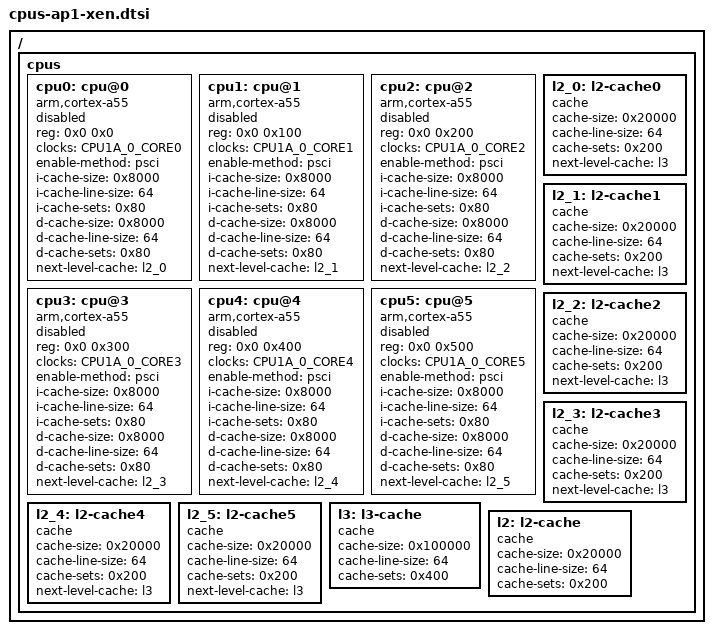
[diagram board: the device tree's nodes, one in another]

/ {
        cpus {
		#address-cells = <2>;
		#size-cells = <0>;

		cpu0: cpu@0 {
			device_type = "cpu";
			compatible = "arm,cortex-a55", "arm,armv8";
			reg = <0x0 0x0>;
			clocks = <&CPU1A_0_CORE0>;
			clock-names = "cpu0";
			enable-method = "psci";
			i-cache-size = <0x8000>;
			i-cache-line-size = <64>;
			i-cache-sets = <0x80>;
			d-cache-size = <0x8000>;
			d-cache-line-size = <64>;
			d-cache-sets = <0x80>;
			next-level-cache = <&l2_0>;
			status = "disabled";
		};

		cpu1: cpu@1 {
			device_type = "cpu";
			compatible = "arm,cortex-a55", "arm,armv8";
			reg = <0x0 0x100>;
			clocks = <&CPU1A_0_CORE1>;
			clock-names = "cpu1";
			enable-method = "psci";
			i-cache-size = <0x8000>;
			i-cache-line-size = <64>;
			i-cache-sets = <0x80>;
			d-cache-size = <0x8000>;
			d-cache-line-size = <64>;
			d-cache-sets = <0x80>;
			next-level-cache = <&l2_1>;
			status = "disabled";
		};

		cpu2: cpu@2 {
			device_type = "cpu";
			compatible = "arm,cortex-a55", "arm,armv8";
			reg = <0x0 0x200>;
			clocks = <&CPU1A_0_CORE2>;
			clock-names = "cpu2";
			enable-method = "psci";
			i-cache-size = <0x8000>;
			i-cache-line-size = <64>;
			i-cache-sets = <0x80>;
			d-cache-size = <0x8000>;
			d-cache-line-size = <64>;
			d-cache-sets = <0x80>;
			next-level-cache = <&l2_2>;
			status = "disabled";
		};

		cpu3: cpu@3 {
			device_type = "cpu";
			compatible = "arm,cortex-a55", "arm,armv8";
			reg = <0x0 0x300>;
			clocks = <&CPU1A_0_CORE3>;
			clock-names = "cpu3";
			enable-method = "psci";
			i-cache-size = <0x8000>;
			i-cache-line-size = <64>;
			i-cache-sets = <0x80>;
			d-cache-size = <0x8000>;
			d-cache-line-size = <64>;
			d-cache-sets = <0x80>;
			next-level-cache = <&l2_3>;
			status = "disabled";
		};

		cpu4: cpu@4 {
			device_type = "cpu";
			compatible = "arm,cortex-a55", "arm,armv8";
			reg = <0x0 0x400>;
			clocks = <&CPU1A_0_CORE4>;
			clock-names = "cpu4";
			enable-method = "psci";
			i-cache-size = <0x8000>;
			i-cache-line-size = <64>;
			i-cache-sets = <0x80>;
			d-cache-size = <0x8000>;
			d-cache-line-size = <64>;
			d-cache-sets = <0x80>;
			next-level-cache = <&l2_4>;
			status = "disabled";
		};

		cpu5: cpu@5 {
			device_type = "cpu";
			compatible = "arm,cortex-a55", "arm,armv8";
			reg = <0x0 0x500>;
			clocks = <&CPU1A_0_CORE5>;
			clock-names = "cpu5";
			enable-method = "psci";
			i-cache-size = <0x8000>;
			i-cache-line-size = <64>;
			i-cache-sets = <0x80>;
			d-cache-size = <0x8000>;
			d-cache-line-size = <64>;
			d-cache-sets = <0x80>;
			next-level-cache = <&l2_5>;
			status = "disabled";
		};

		l2_0: l2-cache0 {
			compatible = "cache";
			cache-size = <0x20000>;
			cache-line-size = <64>;
			cache-sets = <0x200>;
			next-level-cache = <&l3>;
		};

		l2_1: l2-cache1 {
			compatible = "cache";
			cache-size = <0x20000>;
			cache-line-size = <64>;
			cache-sets = <0x200>;
			next-level-cache = <&l3>;
		};

		l2_2: l2-cache2 {
			compatible = "cache";
			cache-size = <0x20000>;
			cache-line-size = <64>;
			cache-sets = <0x200>;
			next-level-cache = <&l3>;
		};

		l2_3: l2-cache3 {
			compatible = "cache";
			cache-size = <0x20000>;
			cache-line-size = <64>;
			cache-sets = <0x200>;
			next-level-cache = <&l3>;
		};

		l2_4: l2-cache4 {
			compatible = "cache";
			cache-size = <0x20000>;
			cache-line-size = <64>;
			cache-sets = <0x200>;
			next-level-cache = <&l3>;
		};

		l2_5: l2-cache5 {
			compatible = "cache";
			cache-size = <0x20000>;
			cache-line-size = <64>;
			cache-sets = <0x200>;
			next-level-cache = <&l3>;
		};

		l3: l3-cache {
			compatible = "cache";
			cache-size = <0x100000>;
			cache-line-size = <64>;
			cache-sets = <0x400>;
		};

		l2: l2-cache {
			compatible = "cache";
			cache-size = <0x20000>;
			cache-line-size = <64>;
			cache-sets = <0x200>;
		};
	};
};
